# ATSAMV71N19 device description
Architecture: CORTEX-M7; Family: SAMV; Series: SAMV71
Registers are 32-bit, read-write, no defined reset value unless marked. A register's access mark holds for its fields unless they carry their own. Offsets are from the block's base; [hi:lo] are bit positions; {n}, {i} and the like mark numbered series.

## UTMI — USB Transmitter Interface Macrocell
Instances: UTMI 0x400E0400
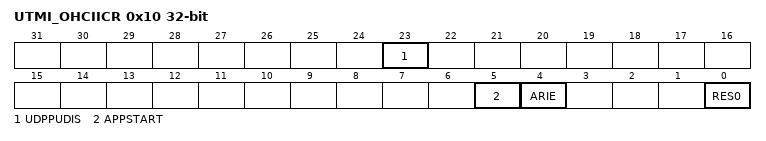
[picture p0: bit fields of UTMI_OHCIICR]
0x10 UTMI_OHCIICR — OHCI Interrupt Configuration Register
  [23] UDPPUDIS — USB Device Pull-up Disable
  [5] APPSTART — Reserved
  [4] ARIE — OHCI Asynchronous Resume Interrupt Enable
  [0] RES0 — USB PORTx Reset
0x30 UTMI_CKTRIM — UTMI Clock Trimming Register
  [1:0] FREQ — UTMI Reference Clock Frequency
    0=XTAL12 (12 MHz reference clock); 1=XTAL16 (16 MHz reference clock)

## WDT — Watchdog Timer
Instances: WDT 0x400E1850
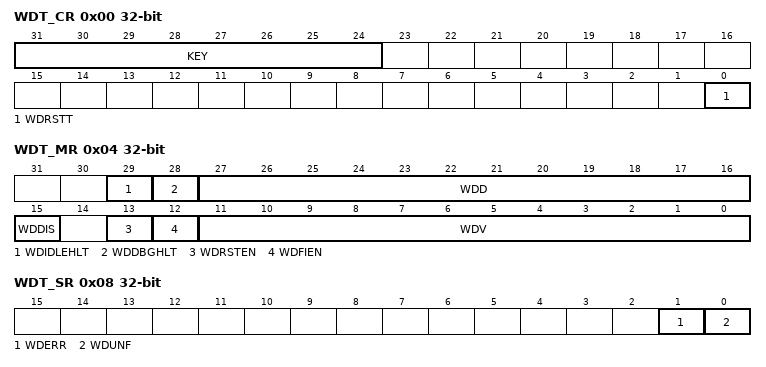
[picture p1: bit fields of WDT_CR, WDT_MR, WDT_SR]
0x00 WDT_CR wo — Control Register
  [31:24] KEY — Password
    165=PASSWD (Writing any other value in this field aborts the write operation.)
  [0] WDRSTT — Watchdog Restart
0x04 WDT_MR — Mode Register
  [29] WDIDLEHLT — Watchdog Idle Halt
  [28] WDDBGHLT — Watchdog Debug Halt
  [27:16] WDD — Watchdog Delta Value
  [15] WDDIS — Watchdog Disable
  [13] WDRSTEN — Watchdog Reset Enable
  [12] WDFIEN — Watchdog Fault Interrupt Enable
  [11:0] WDV — Watchdog Counter Value
0x08 WDT_SR ro — Status Register
  [1] WDERR — Watchdog Error (cleared on read)
  [0] WDUNF — Watchdog Underflow (cleared on read)

## GPNVMBITS (FUSES module)
Instances: GPNVMBITS 0 in fuses
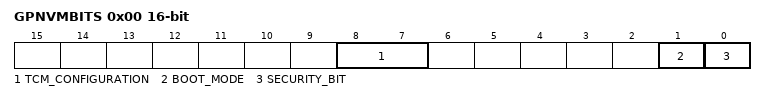
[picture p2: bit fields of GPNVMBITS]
0x00 GPNVMBITS 16-bit
  [8:7] TCM_CONFIGURATION
  [1] BOOT_MODE — Boot Mode Selection
  [0] SECURITY_BIT ro

## LOCKBIT
Instances: LOCKBIT 0 in lockbits
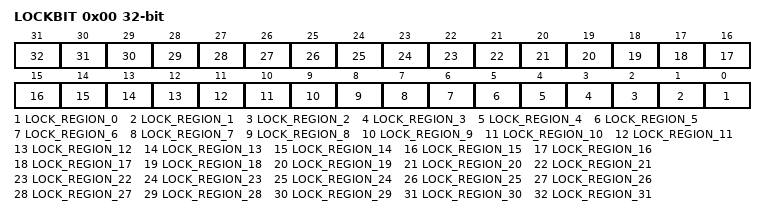
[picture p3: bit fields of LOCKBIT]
0x00 LOCKBIT — Lock Bits
  [n] LOCK_REGION_{n} (n=0..31)

## SCnSCB — System control Register not in SCB
Instances: SCnSCB 0xE000E000
0x04 ICTR ro reset 0x0 — Interrupt Controller Type Register
  [3:0] INTLINESNUM — Total number of interrupt lines supported by an implementation, defined in groups of 32
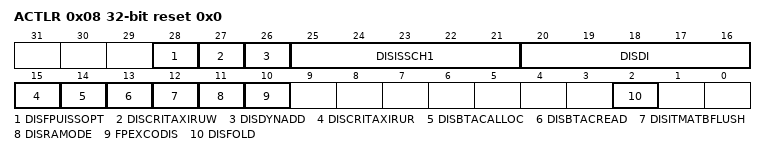
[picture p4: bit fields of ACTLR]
0x08 ACTLR access not given reset 0x0 — Auxiliary Control Register
  [28] DISFPUISSOPT — Disables dynamic allocation of ADD and SUB instructions
  [27] DISCRITAXIRUW — Disable critical AXI read-under-write
  [26] DISDYNADD — Disables dynamic allocation of ADD and SUB instructions
  [25:21] DISISSCH1
  [20:16] DISDI
  [15] DISCRITAXIRUR
  [14] DISBTACALLOC
  [13] DISBTACREAD
  [12] DISITMATBFLUSH — Disables ITM and DWT ATB flush
  [11] DISRAMODE — Disables dynamic read allocate mode for Write-Back Write-Allocate memory regions
  [10] FPEXCODIS — Disables FPU exception outputs
  [2] DISFOLD — Disables folding of IT instructions

## SysTick — System timer Registers
Instances: SysTick 0xE000E010
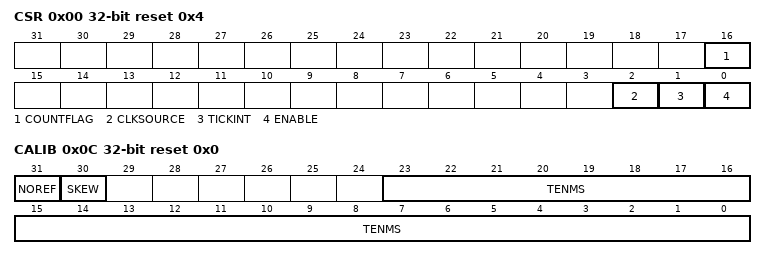
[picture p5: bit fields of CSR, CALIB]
0x00 CSR access not given reset 0x4 — Control and Status Register
  [16] COUNTFLAG — Returns 1 if timer counted to 0 since last time this was read
  [2] CLKSOURCE — Indicates the clock source
    0=external clock; 1=processor clock
  [1] TICKINT — Enables SysTick exception request
    0=counting down to 0 does not assert the SysTick exception request; 1=counting down to 0 asserts the SysTick exception request
  [0] ENABLE — Enables the counter
    0=counter disabled; 1=counter enabled
0x04 RVR access not given reset 0x0 — Reload Value Register
  [23:0] RELOAD — Value to load into the SysTick Current Value Register when the counter reaches 0
0x08 CVR access not given reset 0x0 — Current Value Register
  [23:0] CURRENT — Current value at the time the register is accessed
0x0C CALIB ro reset 0x0 — Calibration Value Register
  [31] NOREF — Indicates whether the device provides a reference clock to the processor
    0=The reference clock is provided; 1=The reference clock is not provided
  [30] SKEW — Indicates whether the TENMS value is exact
    0=10ms calibration value is exact; 1=10ms calibration value is inexact, because of the clock frequency
  [23:0] TENMS — Reload value to use for 10ms timing

## NVIC — Nested Vectored Interrupt Controller
Instances: NVIC 0xE000E100
{0x0+4i} ISER[{i}] (i=0..7) access not given reset 0x0 — Interrupt Set Enable Register n
  [31:0] SETENA — Interrupt set enable bits
{0x80+4i} ICER[{i}] (i=0..7) access not given reset 0x0 — Interrupt Clear Enable Register n
  [31:0] CLRENA — Interrupt clear-enable bits
{0x100+4i} ISPR[{i}] (i=0..7) access not given reset 0x0 — Interrupt Set Pending Register n
  [31:0] SETPEND — Interrupt set-pending bits
{0x180+4i} ICPR[{i}] (i=0..7) access not given reset 0x0 — Interrupt Clear Pending Register n
  [31:0] CLRPEND — Interrupt clear-pending bits
{0x200+4i} IABR[{i}] (i=0..7) access not given reset 0x0 — Interrupt Active bit Register n
  [31:0] ACTIVE — Interrupt active flags
{0x300+i} IP[{i}] (i=0..239) 8-bit access not given reset 0x0 — Interrupt Priority Register (8Bit wide) n
  [7:0] PRI0 — Priority of interrupt 0
0xE00 STIR wo reset 0x0 — Software Trigger Interrupt Register
  [8:0] INTID — Interrupt ID of the interrupt to trigger, in the range 0-239. For example, a value of 0x03 specifies interrupt IRQ3.

## Notices in the file
Copyright (c) 2017 Microchip Technology Inc.
SPDX-License-Identifier: Apache-2.0
Licensed under the Apache License, Version 2.0 (the "License");
you may not use this file except in compliance with the License.
You may obtain a copy of the License at
http://www.apache.org/licenses/LICENSE-2.0
Unless required by applicable law or agreed to in writing, software
distributed under the License is distributed on an "AS IS" BASIS,
WITHOUT WARRANTIES OR CONDITIONS OF ANY KIND, either express or implied.
See the License for the specific language governing permissions and
limitations under the License.
